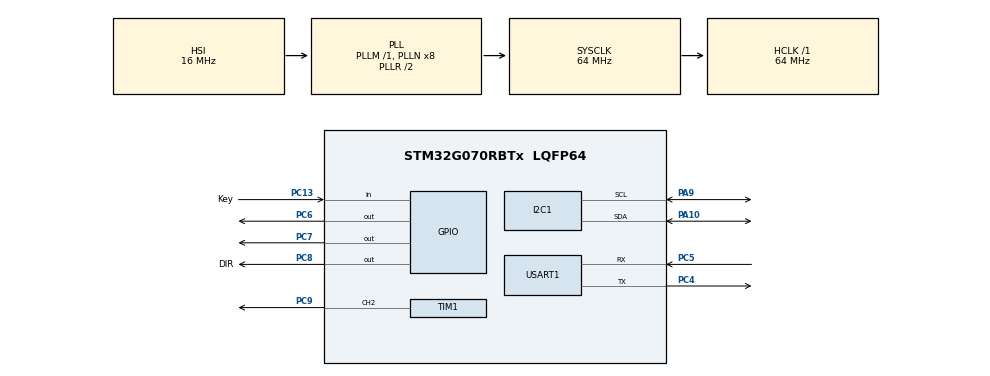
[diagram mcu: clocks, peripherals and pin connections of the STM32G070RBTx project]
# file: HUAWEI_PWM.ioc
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I2C1.Timing=0x10B17DB5
Mcu.Family=STM32G0
Mcu.Name=STM32G070RBTx
Mcu.Package=LQFP64
NVIC.TIM3_IRQn=true\:0\:0\:false\:false\:true\:true\:true\:true
NVIC.TIM6_IRQn=true\:0\:0\:false\:false\:true\:true\:true\:true
PA10.Mode=I2C
PA10.Signal=I2C1_SDA
PA13.Mode=Serial_Wire
PA13.Signal=SYS_SWDIO
PA14-BOOT0.Mode=Serial_Wire
PA14-BOOT0.Signal=SYS_SWCLK
PA9.Mode=I2C
PA9.Signal=I2C1_SCL
PC13.GPIO_Label=Key
PC13.GPIO_PuPd=GPIO_PULLUP
PC13.Signal=GPIO_Input
PC14-OSC32_IN\ (PC14).Mode=LSE-External-Oscillator
PC14-OSC32_IN\ (PC14).Signal=RCC_OSC32_IN
PC15-OSC32_OUT\ (PC15).Mode=LSE-External-Oscillator
PC15-OSC32_OUT\ (PC15).Signal=RCC_OSC32_OUT
PC4.Mode=Asynchronous
PC4.Signal=USART1_TX
PC5.Mode=Asynchronous
PC5.Signal=USART1_RX
PC6.GPIO_PuPd=GPIO_PULLDOWN
PC6.Signal=GPIO_Output
PC7.GPIO_PuPd=GPIO_PULLDOWN
PC7.Signal=GPIO_Output
PC8.GPIO_Label=DIR
PC8.PinState=GPIO_PIN_SET
PC8.Signal=GPIO_Output
PC9.Signal=S_TIM1_CH2
PF0-OSC_IN\ (PF0).Mode=HSE-External-Oscillator
PF0-OSC_IN\ (PF0).Signal=RCC_OSC_IN
PF1-OSC_OUT\ (PF1).Mode=HSE-External-Oscillator
PF1-OSC_OUT\ (PF1).Signal=RCC_OSC_OUT
ProjectManager.HeapSize=0x200
ProjectManager.StackSize=0x400
ProjectManager.TargetToolchain=EWARM V8.50
RCC.ADCFreq_Value=64000000
RCC.AHBFreq_Value=64000000
RCC.CortexFreq_Value=64000000
RCC.EXTERNAL_CLOCK_VALUE=48000
RCC.HCLKFreq_Value=64000000
RCC.HSE_VALUE=8000000
RCC.HSI_VALUE=16000000
RCC.SYSCLKFreq_VALUE=64000000
RCC.SYSCLKSource=RCC_SYSCLKSOURCE_PLLCLK
RCC.VCOOutputFreq_Value=128000000
SH.S_TIM1_CH2.0=TIM1_CH2,PWM Generation2 CH2
TIM1.AutoReloadPreload=TIM_AUTORELOAD_PRELOAD_DISABLE
TIM1.Channel-PWM\ Generation2\ CH2=TIM_CHANNEL_2
TIM1.Period=1000-1
TIM1.Prescaler=64-1
TIM1.Pulse-PWM\ Generation2\ CH2=50-1
TIM1.TIM_MasterOutputTrigger=TIM_TRGO_OC1
TIM1.TIM_MasterOutputTrigger2=TIM_TRGO2_UPDATE
TIM3.Period=10000-1
TIM3.Prescaler=64-1
TIM3.TIM_MasterOutputTrigger=TIM_TRGO_UPDATE
TIM6.AutoReloadPreload=TIM_AUTORELOAD_PRELOAD_ENABLE
TIM6.Period=10000-1
TIM6.Prescaler=64-1
TIM6.TIM_MasterOutputTrigger=TIM_TRGO_UPDATE
USART1.VirtualMode-Asynchronous=VM_ASYNC
VP_TIM1_VS_ClockSourceINT.Mode=Internal
VP_TIM3_VS_ClockSourceINT.Mode=Internal
VP_TIM6_VS_ClockSourceINT.Mode=Enable_Timer
board=custom

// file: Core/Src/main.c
/* USER CODE BEGIN Header */
/**
  ******************************************************************************
  * @file           : main.c
  * @brief          : Main program body
  ******************************************************************************
  * @attention
  *
  * Copyright (c) 2025 STMicroelectronics.
  * All rights reserved.
  *
  * This software is licensed under terms that can be found in the LICENSE file
  * in the root directory of this software component.
  * If no LICENSE file comes with this software, it is provided AS-IS.
  *
  ******************************************************************************
  */
/* USER CODE END Header */
#include "main.h"
#include "i2c.h"
#include "tim.h"
#include "usart.h"
#include "gpio.h"

/* USER CODE BEGIN Includes */
#include "AS5600.h"
/* USER CODE END Includes */

/* USER CODE BEGIN PV */
uint8_t PID_Flag = 0;
uint16_t Raw_Angle;
char PID_String[1024] = {0};
char buffer[256] = {0};
/* USER CODE END PV */

void SystemClock_Config(void);

int main(void)
{

  /* USER CODE BEGIN 1 */
  static uint8_t Key_Flag = 0,PWM_Flag = 0;
  /* USER CODE END 1 */

  /* MCU Configuration--------------------------------------------------------*/

  /* Reset of all peripherals, Initializes the Flash interface and the Systick. */
  HAL_Init();

  /* Configure the system clock */
  SystemClock_Config();

  /* Initialize all configured peripherals */
  MX_GPIO_Init();
  MX_TIM1_Init();
  MX_TIM3_Init();
  MX_USART1_UART_Init();
  MX_TIM6_Init();
  MX_I2C1_Init();
  /* USER CODE BEGIN 2 */

  //

    //
  HAL_TIM_PWM_Start(&htim1,TIM_CHANNEL_2);
  HAL_TIM_Base_Start_IT(&htim3);
  HAL_TIM_Base_Start_IT(&htim6);

  /* USER CODE END 2 */

  /* Infinite loop */
  /* USER CODE BEGIN WHILE */
  while (1)
  {
    /*
    if (HAL_GPIO_ReadPin(GPIOC,GPIO_PIN_13) == GPIO_PIN_RESET)
    {
      HAL_Delay(10);
      if (HAL_GPIO_ReadPin(GPIOC,GPIO_PIN_13) == GPIO_PIN_SET)
      {
        if (Key_Flag)
        {
          TIM1->ARR = 60-1;
          TIM1->CCR2 = 30-1;

          Key_Flag = 0;
        }else {
          TIM1->ARR = 100-1;
          TIM1->CCR2 = 50-1;
          Key_Flag = 1;
         }
       }
    }
*/

    /* USER CODE END WHILE */

  }
}

void SystemClock_Config(void)
{
  RCC_OscInitTypeDef RCC_OscInitStruct = {0};
  RCC_ClkInitTypeDef RCC_ClkInitStruct = {0};

  /** Configure the main internal regulator output voltage
  */
  HAL_PWREx_ControlVoltageScaling(PWR_REGULATOR_VOLTAGE_SCALE1);

  /** Initializes the RCC Oscillators according to the specified parameters
  * in the RCC_OscInitTypeDef structure.
  */
  RCC_OscInitStruct.OscillatorType = RCC_OSCILLATORTYPE_HSI;
  RCC_OscInitStruct.HSIState = RCC_HSI_ON;
  RCC_OscInitStruct.HSIDiv = RCC_HSI_DIV1;
  RCC_OscInitStruct.HSICalibrationValue = RCC_HSICALIBRATION_DEFAULT;
  RCC_OscInitStruct.PLL.PLLState = RCC_PLL_ON;
  RCC_OscInitStruct.PLL.PLLSource = RCC_PLLSOURCE_HSI;
  RCC_OscInitStruct.PLL.PLLM = RCC_PLLM_DIV1;
  RCC_OscInitStruct.PLL.PLLN = 8;
  RCC_OscInitStruct.PLL.PLLP = RCC_PLLP_DIV2;
  RCC_OscInitStruct.PLL.PLLR = RCC_PLLR_DIV2;
  if (HAL_RCC_OscConfig(&RCC_OscInitStruct) != HAL_OK)
  {
    Error_Handler();
  }

  /** Initializes the CPU, AHB and APB buses clocks
  */
  RCC_ClkInitStruct.ClockType = RCC_CLOCKTYPE_HCLK|RCC_CLOCKTYPE_SYSCLK
                              |RCC_CLOCKTYPE_PCLK1;
  RCC_ClkInitStruct.SYSCLKSource = RCC_SYSCLKSOURCE_PLLCLK;
  RCC_ClkInitStruct.AHBCLKDivider = RCC_SYSCLK_DIV1;
  RCC_ClkInitStruct.APB1CLKDivider = RCC_HCLK_DIV1;

  if (HAL_RCC_ClockConfig(&RCC_ClkInitStruct, FLASH_LATENCY_2) != HAL_OK)
  {
    Error_Handler();
  }
}

void Error_Handler(void)
{
  __disable_irq();
  while (1)
  {
  }
}
